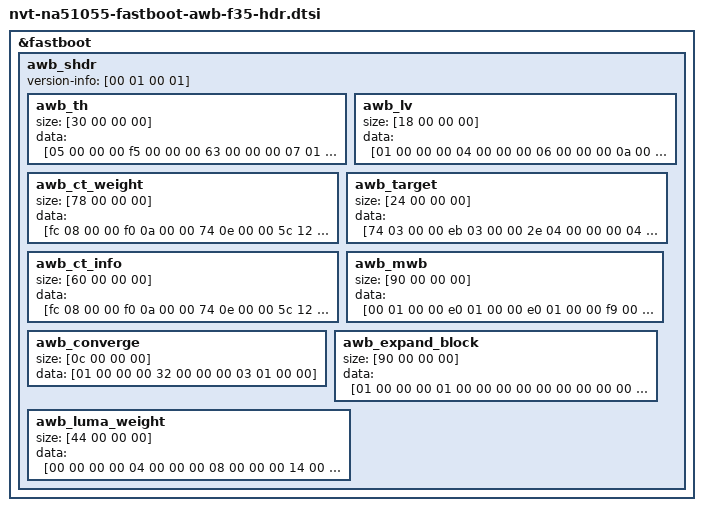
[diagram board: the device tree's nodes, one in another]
/*
 * Novatek Ltd. NA51055 BSP part of dts
 *
 * Cortex-A9
 *
 */

&fastboot {
	    awb_shdr {
		version-info = [00 01 00 01];
		awb_th {
			size = [30 00 00 00];
			data = [05 00 00 00 f5 00 00 00 63 00 00 00 07 01 00 00 cd ff ff ff 66 00 00 00 37 00 00 00 a0 00 00 00 2d 00 00 00 68 00 00 00 2b 00 00 00 3e 00 00 00];
		};
		awb_lv {
			size = [18 00 00 00];
			data = [01 00 00 00 04 00 00 00 06 00 00 00 0a 00 00 00 0e 00 00 00 1a 00 00 00];
		};
		awb_ct_weight {
			size = [78 00 00 00];
			data = [fc 08 00 00 f0 0a 00 00 74 0e 00 00 5c 12 00 00 64 19 00 00 f8 2a 00 00 55 03 00 00 74 03 00 00 b5 03 00 00 eb 03 00 00 2e 04 00 00 69 04 00 00 01 00 00 00 01 00 00 00 01 00 00 00 01 00 00 00 01 00 00 00 01 00 00 00 01 00 00 00 01 00 00 00 01 00 00 00 03 00 00 00 01 00 00 00 01 00 00 00 01 00 00 00 01 00 00 00 01 00 00 00 01 00 00 00 01 00 00 00 01 00 00 00];
		};
		awb_target {
			size = [24 00 00 00];
			data = [74 03 00 00 eb 03 00 00 2e 04 00 00 00 04 00 00 00 04 00 00 00 04 00 00 00 04 00 00 00 04 00 00 00 04 00 00];
		};
		awb_ct_info {
			size = [60 00 00 00];
			data = [fc 08 00 00 f0 0a 00 00 74 0e 00 00 5c 12 00 00 64 19 00 00 f8 2a 00 00 00 01 00 00 18 01 00 00 55 01 00 00 86 01 00 00 bd 01 00 00 16 02 00 00 00 01 00 00 00 01 00 00 00 01 00 00 00 01 00 00 00 01 00 00 00 01 00 00 57 02 00 00 38 02 00 00 f6 01 00 00 b4 01 00 00 61 01 00 00 38 01 00 00];
		};
		awb_mwb {
			size = [90 00 00 00];
			data = [00 01 00 00 e0 01 00 00 e0 01 00 00 f9 00 00 00 1d 01 00 00 00 01 00 00 00 01 00 00 00 01 00 00 00 01 00 00 00 01 00 00 00 01 00 00 00 01 00 00 00 01 00 00 00 01 00 00 00 01 00 00 00 01 00 00 00 01 00 00 00 01 00 00 00 01 00 00 00 01 00 00 00 01 00 00 00 01 00 00 00 01 00 00 00 01 00 00 00 01 00 00 79 01 00 00 40 01 00 00 47 03 00 00 26 03 00 00 00 01 00 00 00 01 00 00 00 01 00 00 00 01 00 00 00 01 00 00 00 01 00 00 00 01 00 00];
		};
		awb_converge {
			size = [0c 00 00 00];
			data = [01 00 00 00 32 00 00 00 03 01 00 00];
		};
		awb_expand_block {
			size = [90 00 00 00];
			data = [01 00 00 00 01 00 00 00 00 00 00 00 00 00 00 00 06 00 00 00 06 00 00 00 06 00 00 00 06 00 00 00 0a 00 00 00 0a 00 00 00 0a 00 00 00 0a 00 00 00 05 00 00 00 05 00 00 00 05 00 00 00 05 00 00 00 f5 00 00 00 f5 00 00 00 f5 00 00 00 f5 00 00 00 8a 00 00 00 89 00 00 00 5b 00 00 00 72 00 00 00 97 00 00 00 96 00 00 00 69 00 00 00 80 00 00 00 0d 00 00 00 f5 ff ff ff 12 00 00 00 20 00 00 00 19 00 00 00 02 00 00 00 20 00 00 00 cb ff ff ff];
		};
		awb_luma_weight {
			size = [44 00 00 00];
			data = [00 00 00 00 04 00 00 00 08 00 00 00 14 00 00 00 20 00 00 00 c0 00 00 00 d0 00 00 00 e0 00 00 00 f0 00 00 00 01 00 00 00 01 00 00 00 01 00 00 00 01 00 00 00 01 00 00 00 01 00 00 00 01 00 00 00 01 00 00 00];
		};
	};
};
